# PIC32CX2051BZ62132 register map
Vendor: Microchip Technology; Series: PIC32CXBZ62; File version: 0
CPU: CM4 r0p1, little endian, MPU, FPU, 3 interrupt priority bits, 58 interrupts
Registers are 32-bit, read-write, reset 0x0 unless marked. A register's access mark holds for its fields unless they carry their own. Offsets are from the block's base; [hi:lo] are bit positions; {n}, {i} and the like mark numbered series; 'fields as' and 'values as' point back to an identical list.

## MPU — Memory Protection Unit
Base 0xE000ED90
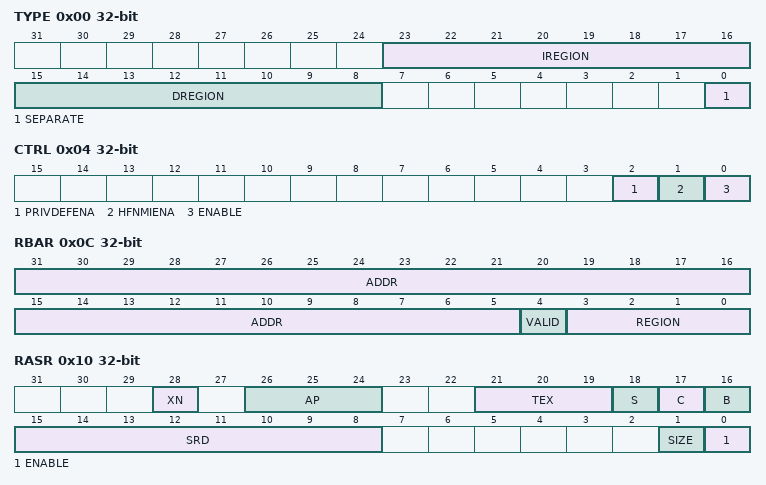
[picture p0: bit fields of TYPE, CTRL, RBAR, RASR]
0x00 TYPE ro — MPU Type Register
  [23:16] IREGION — Number of Instruction Regions
  [15:8] DREGION — Number of Data Regions
  [0] SEPARATE — Separate instruction and Data Memory MapsRegions
0x04 CTRL — MPU Control Register
  [2] PRIVDEFENA — Enables privileged software access to default memory map
  [1] HFNMIENA — Enable Hard Fault and NMI handlers
  [0] ENABLE — MPU Enable
0x08 RNR — MPU Region Number Register
  [7:0] REGION — Region referenced by RBAR and RASR
0x0C RBAR — MPU Region Base Address Register
  [31:5] ADDR — Region base address
  [4] VALID — Region number valid
  [3:0] REGION — Region number
0x10 RASR — MPU Region Attribute and Size Register
  [28] XN — Execute Never Attribute
  [26:24] AP — Access Permission
  [21:19] TEX — TEX bit
  [18] S — Shareable bit
  [17] C — Cacheable bit
  [16] B — Bufferable bit
  [15:8] SRD — Sub-region disable
  [1] SIZE — Region Size
  [0] ENABLE — Region Enable
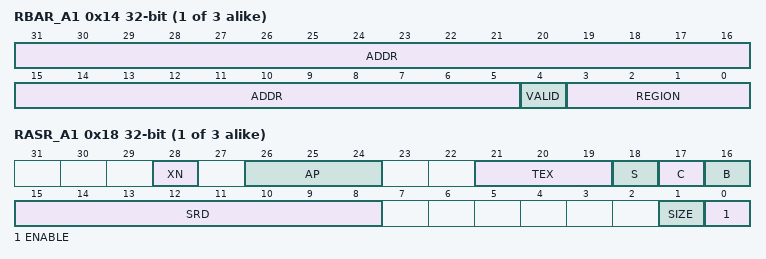
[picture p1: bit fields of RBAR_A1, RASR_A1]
{0xC+8i} RBAR_A{i} (i=1..3) — MPU Alias {i} Region Base Address Register
  fields as RBAR
{0x10+8i} RASR_A{i} (i=1..3) — MPU Alias {i} Region Attribute and Size Register
  fields as RASR

## NVIC — Nested Vectored Interrupt Controller
Base 0xE000E100
{0x0+4i} ISER[{i}] (i=0..1) — Interrupt Set Enable Register
  [31:0] SETENA — Interrupt set enable bits
{0x80+4i} ICER[{i}] (i=0..1) — Interrupt Clear Enable Register
  [31:0] CLRENA — Interrupt clear-enable bits
{0x100+4i} ISPR[{i}] (i=0..1) — Interrupt Set Pending Register
  [31:0] SETPEND — Interrupt set-pending bits
{0x180+4i} ICPR[{i}] (i=0..1) — Interrupt Clear Pending Register
  [31:0] CLRPEND — Interrupt clear-pending bits
{0x200+4i} IABR[{i}] (i=0..1) — Interrupt Active Bit Register
  [31:0] ACTIVE — Interrupt active bits
{0x300+i} IP[{i}] (i=0..57) 8-bit — Interrupt Priority Register n
  [2:0] PRI0 — Priority of interrupt n
0xE00 STIR wo — Software Trigger Interrupt Register
  [8:0] INTID — Interrupt ID to trigger

## NVM — flash controller
Base 0x44000600
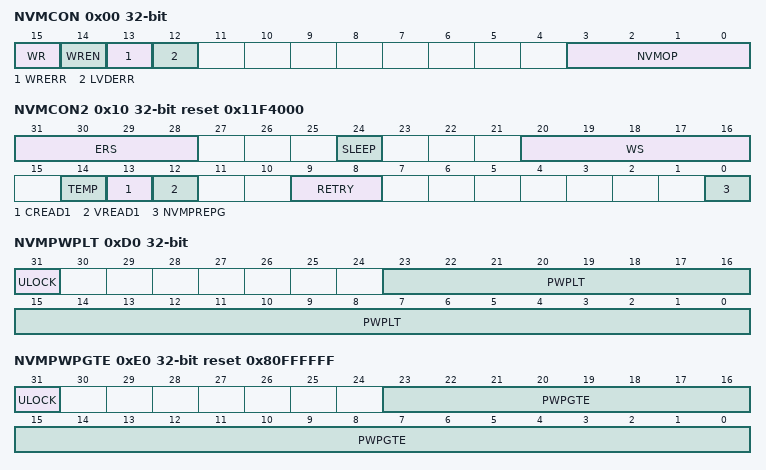
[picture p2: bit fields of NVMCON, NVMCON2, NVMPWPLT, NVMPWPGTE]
0x00 NVMCON
  [15] WR, [14] WREN, [13] WRERR, [12] LVDERR, [3:0] NVMOP
0x04 NVMCONCLR
0x08 NVMCONSET
0x0C NVMCONINV
0x10 NVMCON2 reset 0x11F4000
  [31:28] ERS, [24] SLEEP, [20:16] WS, [14] TEMP, [13] CREAD1, [12] VREAD1, [9:8] RETRY, [0] NVMPREPG
0x14 NVMCON2CLR
0x18 NVMCON2SET
0x1C NVMCON2INV
0x20 NVMKEY
0x30 NVMADDR
{0x40+0x10*i} NVMDATA{i} (i=0..7)
0xC0 NVMSRCADDR
0xD0 NVMPWPLT
  [31] ULOCK, [23:0] PWPLT
0xD4 NVMPWPLTCLR
0xD8 NVMPWPLTSET
0xDC NVMPWPLTINV
0xE0 NVMPWPGTE reset 0x80FFFFFF
  [31] ULOCK, [23:0] PWPGTE
0xE4 NVMPWPGTECLR
0xE8 NVMPWPGTESET
0xEC NVMPWPGTEINV
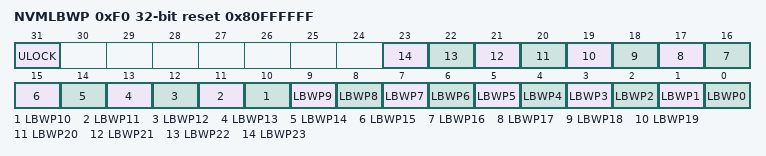
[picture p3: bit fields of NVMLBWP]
0xF0 NVMLBWP reset 0x80FFFFFF
  [31] ULOCK, [n] LBWP{n} (n=0..23)
0xF4 NVMLBWPCLR
0xF8 NVMLBWPSET
0xFC NVMLBWPINV

## PAC — Peripheral Access Controller
Base 0x40000000
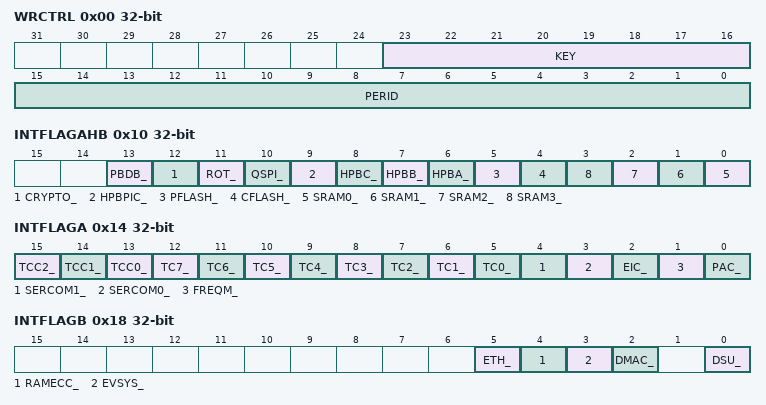
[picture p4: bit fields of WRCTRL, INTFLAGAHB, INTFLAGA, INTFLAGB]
0x00 WRCTRL — Write control
  [23:16] KEY — Peripheral access control key
    0=OFF (No action); 1=CLR (Clear protection); 2=SET (Set protection); 3=SETLCK (Set and lock protection)
  [15:0] PERID — Peripheral identifier
0x04 EVCTRL 8-bit — Event control
  [0] ERREO — Peripheral acess error event output
0x08 INTENCLR 8-bit write-1-clears — Interrupt enable clear
  [0] ERR — Peripheral access error interrupt disable
0x09 INTENSET 8-bit write-1-sets — Interrupt enable set
  [0] ERR — Peripheral access error interrupt enable
0x10 INTFLAGAHB write-1-clears — Bridge interrupt flag status
  [13] PBDB_
  [12] CRYPTO_
  [11] ROT_
  [10] QSPI_
  [9] HPBPIC_ — HPBPIC0
  [8] HPBC_
  [7] HPBB_
  [6] HPBA_
  [5] PFLASH_
  [4] CFLASH_
  [n] SRAM{n}_ (n=0..3)
0x14 INTFLAGA write-1-clears — Peripheral interrupt flag status - Bridge A
  [15] TCC2_, [14] TCC1_, [13] TCC0_, [n+5] TC{n}_ (n=0..7), [4] SERCOM1_, [3] SERCOM0_, [2] EIC_, [1] FREQM_, [0] PAC_
0x18 INTFLAGB write-1-clears — Peripheral interrupt flag status - Bridge B
  [5] ETH_, [4] RAMECC_, [3] EVSYS_, [2] DMAC_, [0] DSU_
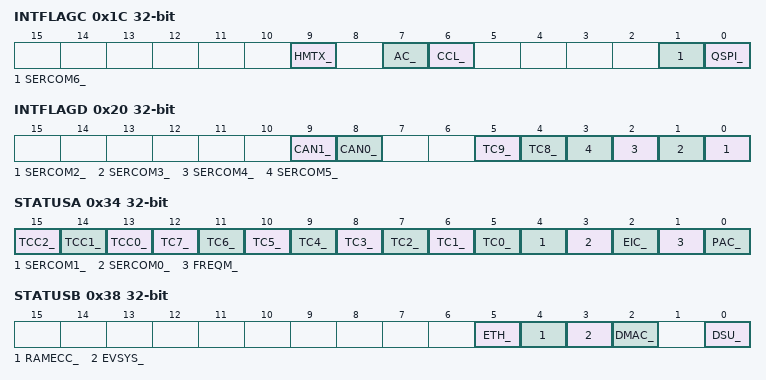
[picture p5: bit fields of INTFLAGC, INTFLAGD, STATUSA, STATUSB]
0x1C INTFLAGC write-1-clears — Peripheral interrupt flag status - Bridge C
  [9] HMTX_, [7] AC_, [6] CCL_, [1] SERCOM6_, [0] QSPI_
0x20 INTFLAGD write-1-clears — Peripheral interrupt flag status - Bridge D
  [9] CAN1_, [8] CAN0_, [5] TC9_, [4] TC8_, [n-2] SERCOM{n}_ (n=2..5)
0x34 STATUSA ro — Peripheral write protection status - Bridge A
  [15] TCC2_ — TCC2 APB Protect Enable
  [14] TCC1_ — TCC1 APB Protect Enable
  [13] TCC0_ — TCC0 APB Protect Enable
  [n+5] TC{n}_ (n=0..7) — TC{n} APB Protect Enable
  [4] SERCOM1_ — SERCOM1 APB Protect Enable
  [3] SERCOM0_ — SERCOM0 APB Protect Enable
  [2] EIC_ — EIC APB Protect Enable
  [1] FREQM_ — FREQM APB Protect Enable
  [0] PAC_ — PAC APB Protect Enable
0x38 STATUSB ro — Peripheral write protection status - Bridge B
  [5] ETH_ — ETH APB Protect Enable
  [4] RAMECC_ — RAMECC APB Protect Enable
  [3] EVSYS_ — EVSYS APB Protect Enable
  [2] DMAC_ — DMAC APB Protect Enable
  [0] DSU_ — DSU APB Protect Enable
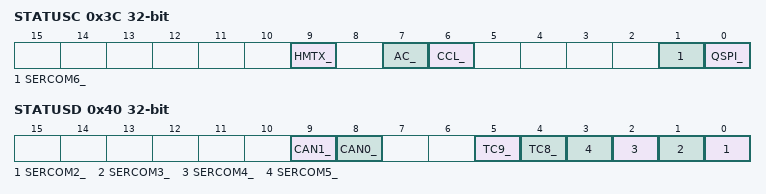
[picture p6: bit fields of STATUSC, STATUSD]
0x3C STATUSC ro — Peripheral write protection status - Bridge C
  [9] HMTX_ — HMTX Protect Enable
  [7] AC_ — AC APB Protect Enable
  [6] CCL_ — CCL APB Protect Enable
  [1] SERCOM6_ — SERCOM6 APB Protect Enable
  [0] QSPI_ — QSPI APB Protect Enable
0x40 STATUSD ro — Peripheral write protection status - Bridge D
  [9] CAN1_ — CAN1 APB Protect Enable
  [8] CAN0_ — CAN0 APB Protect Enable
  [5] TC9_ — TC9 APB Protect Enable
  [4] TC8_ — TC8 APB Protect Enable
  [n-2] SERCOM{n}_ (n=2..5) — SERCOM{n} APB Protect Enable
